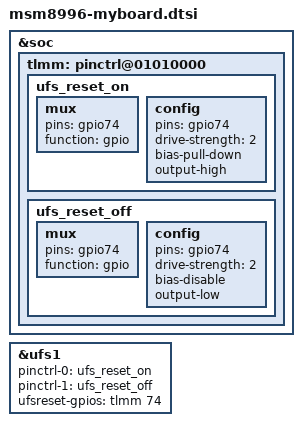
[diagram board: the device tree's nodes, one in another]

&soc {
   tlmm: pinctrl@01010000 {

       ufs_reset_on: ufs_reset_on {
           mux {
               pins = "gpio74";
               function = "gpio";
           };

           config {
               pins = "gpio74";
               drive-strength = <2>;
               bias-pull-down;
               output-high;
           };
       };

       ufs_reset_off: ufs_reset_off {
           mux {
               pins = "gpio74";
               function = "gpio";
           };

           config {
               pins = "gpio74";
               drive-strength = <2>;
               bias-disable;
               output-low;
           };
       };
   };
};

&ufs1 {
   pinctrl-names = "ufs_res_in_on", "ufs_res_in_off";
   pinctrl-0 = <&ufs_reset_on>;
   pinctrl-1 = <&ufs_reset_off>;
   /* H+ hw - invert signal by FET - UFS_RESET_N is low active */
   ufsreset-gpios = <&tlmm 74 0x0>;
};
